VERSION ""

NS_ :

BS_:

BU_: GW Steering Brake

BO_ 256 MSG_SteeringWheelInfo: 3 Steering
 SG_ SIG_SteeringWheelAngle : 8|11@1- (1,0) [-540|540] "degree" Vector__XXX
 SG_ SIG_Crc : 0|8@1+ (1,0) [0|255] "" Vector__XXX

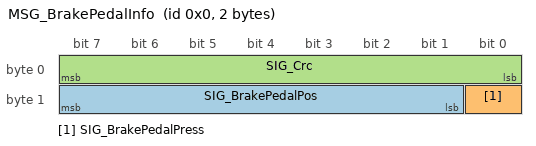
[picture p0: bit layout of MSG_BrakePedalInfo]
BO_ 0 MSG_BrakePedalInfo: 2 Brake
 SG_ SIG_BrakePedalPos : 9|7@1+ (1,0) [0|100] "%" Vector__XXX
 SG_ SIG_BrakePedalPress : 8|1@1+ (1,0) [0|1] "" Vector__XXX
 SG_ SIG_Crc : 0|8@1+ (1,0) [0|255] "" Vector__XXX
